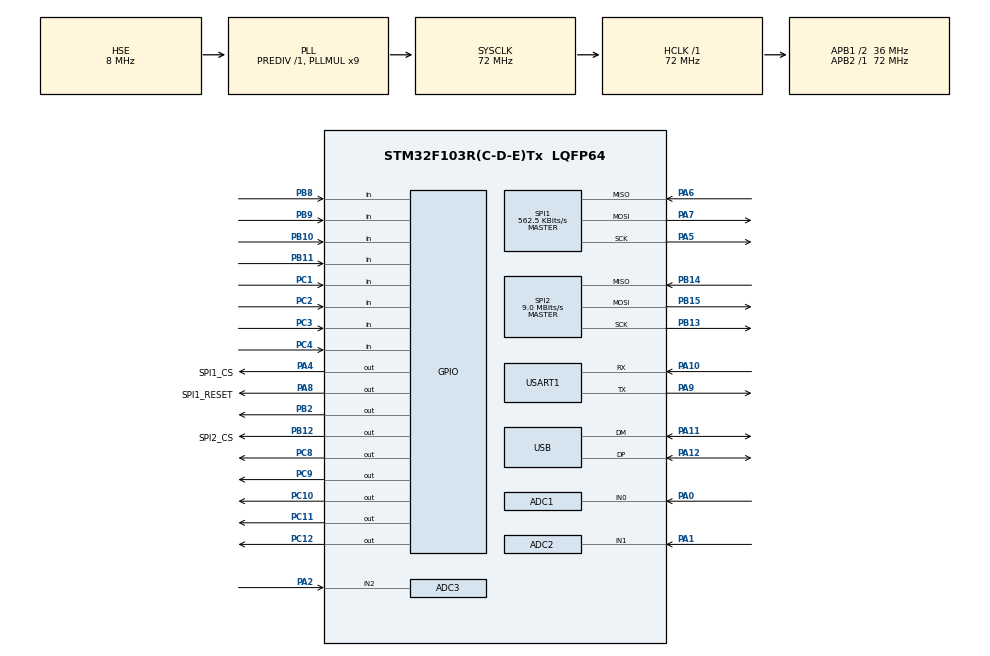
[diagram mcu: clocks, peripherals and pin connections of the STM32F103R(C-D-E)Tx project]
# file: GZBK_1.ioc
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ADC1.Channel-5\#ChannelRegularConversion=ADC_CHANNEL_0
ADC1.ContinuousConvMode=ENABLE
ADC1.NbrOfConversion=1
ADC1.NbrOfConversionFlag=1
ADC1.Rank-5\#ChannelRegularConversion=1
ADC1.SamplingTime-5\#ChannelRegularConversion=ADC_SAMPLETIME_239CYCLES_5
ADC1.master=1
ADC2.Channel-3\#ChannelRegularConversion=ADC_CHANNEL_1
ADC2.ContinuousConvMode=ENABLE
ADC2.NbrOfConversionFlag=1
ADC2.Rank-3\#ChannelRegularConversion=1
ADC2.SamplingTime-3\#ChannelRegularConversion=ADC_SAMPLETIME_1CYCLE_5
ADC3.Channel-0\#ChannelRegularConversion=ADC_CHANNEL_2
ADC3.ContinuousConvMode=ENABLE
ADC3.NbrOfConversion=1
ADC3.NbrOfConversionFlag=1
ADC3.Rank-0\#ChannelRegularConversion=1
ADC3.SamplingTime-0\#ChannelRegularConversion=ADC_SAMPLETIME_1CYCLE_5
Dma.ADC3.0.Direction=DMA_PERIPH_TO_MEMORY
Dma.ADC3.0.Instance=DMA2_Channel5
Dma.ADC3.0.MemDataAlignment=DMA_MDATAALIGN_HALFWORD
Dma.ADC3.0.MemInc=DMA_MINC_ENABLE
Dma.ADC3.0.Mode=DMA_CIRCULAR
Dma.ADC3.0.PeriphDataAlignment=DMA_PDATAALIGN_HALFWORD
Dma.ADC3.0.PeriphInc=DMA_PINC_DISABLE
Dma.ADC3.0.Priority=DMA_PRIORITY_VERY_HIGH
Dma.Request0=ADC3
Mcu.Family=STM32F1
Mcu.Name=STM32F103R(C-D-E)Tx
Mcu.Package=LQFP64
NVIC.DMA2_Channel4_5_IRQn=true\:0\:0\:false\:false\:true\:false\:true
NVIC.PriorityGroup=NVIC_PRIORITYGROUP_4
NVIC.USART1_IRQn=true\:0\:0\:false\:false\:true\:true\:true
NVIC.USB_LP_CAN1_RX0_IRQn=true\:0\:0\:false\:false\:true\:false\:true
PA0-WKUP.Signal=ADCx_IN0
PA1.Signal=ADCx_IN1
PA10.Mode=Asynchronous
PA10.Signal=USART1_RX
PA11.Mode=Device
PA11.Signal=USB_DM
PA12.Mode=Device
PA12.Signal=USB_DP
PA13.Mode=Serial_Wire
PA13.Signal=SYS_JTMS-SWDIO
PA14.Mode=Serial_Wire
PA14.Signal=SYS_JTCK-SWCLK
PA2.Signal=ADCx_IN2
PA4.GPIO_Label=SPI1_CS
PA4.GPIO_PuPd=GPIO_PULLDOWN
PA4.GPIO_Speed=GPIO_SPEED_FREQ_HIGH
PA4.PinState=GPIO_PIN_SET
PA4.Signal=GPIO_Output
PA5.Mode=Full_Duplex_Master
PA5.Signal=SPI1_SCK
PA6.Mode=Full_Duplex_Master
PA6.Signal=SPI1_MISO
PA7.Mode=Full_Duplex_Master
PA7.Signal=SPI1_MOSI
PA8.GPIO_Label=SPI1_RESET
PA8.Signal=GPIO_Output
PA9.Mode=Asynchronous
PA9.Signal=USART1_TX
PB10.GPIO_PuPd=GPIO_PULLDOWN
PB10.Signal=GPIO_Input
PB11.GPIO_PuPd=GPIO_PULLDOWN
PB11.Signal=GPIO_Input
PB12.GPIO_Label=SPI2_CS
PB12.GPIO_PuPd=GPIO_PULLUP
PB12.GPIO_Speed=GPIO_SPEED_FREQ_HIGH
PB12.PinState=GPIO_PIN_SET
PB12.Signal=GPIO_Output
PB13.GPIO_Mode=GPIO_MODE_AF_PP
PB13.Mode=Full_Duplex_Master
PB13.Signal=SPI2_SCK
PB14.GPIO_PuPd=GPIO_PULLUP
PB14.Mode=Full_Duplex_Master
PB14.Signal=SPI2_MISO
PB15.GPIO_Speed=GPIO_SPEED_FREQ_HIGH
PB15.Mode=Full_Duplex_Master
PB15.Signal=SPI2_MOSI
PB2.PinState=GPIO_PIN_SET
PB2.Signal=GPIO_Output
PB8.GPIO_PuPd=GPIO_PULLDOWN
PB8.Signal=GPIO_Input
PB9.GPIO_PuPd=GPIO_PULLDOWN
PB9.Signal=GPIO_Input
PC1.GPIO_PuPd=GPIO_PULLDOWN
PC1.Signal=GPIO_Input
PC10.GPIO_ModeDefaultOutputPP=GPIO_MODE_OUTPUT_PP
PC10.GPIO_PuPd=GPIO_NOPULL
PC10.GPIO_Speed=GPIO_SPEED_FREQ_HIGH
PC10.PinState=GPIO_PIN_SET
PC10.Signal=GPIO_Output
PC11.GPIO_Speed=GPIO_SPEED_FREQ_HIGH
PC11.Signal=GPIO_Output
PC12.GPIO_Speed=GPIO_SPEED_FREQ_HIGH
PC12.PinState=GPIO_PIN_SET
PC12.Signal=GPIO_Output
PC14-OSC32_IN.Mode=LSE-External-Oscillator
PC14-OSC32_IN.Signal=RCC_OSC32_IN
PC15-OSC32_OUT.Mode=LSE-External-Oscillator
PC15-OSC32_OUT.Signal=RCC_OSC32_OUT
PC2.GPIO_PuPd=GPIO_PULLDOWN
PC2.Signal=GPIO_Input
PC3.GPIO_PuPd=GPIO_PULLDOWN
PC3.Signal=GPIO_Input
PC4.GPIO_PuPd=GPIO_PULLDOWN
PC4.Signal=GPIO_Input
PC8.GPIO_ModeDefaultOutputPP=GPIO_MODE_OUTPUT_PP
PC8.GPIO_PuPd=GPIO_NOPULL
PC8.GPIO_Speed=GPIO_SPEED_FREQ_HIGH
PC8.PinState=GPIO_PIN_SET
PC8.Signal=GPIO_Output
PC9.GPIO_Speed=GPIO_SPEED_FREQ_HIGH
PC9.PinState=GPIO_PIN_SET
PC9.Signal=GPIO_Output
PD0-OSC_IN.Mode=HSE-External-Oscillator
PD0-OSC_IN.Signal=RCC_OSC_IN
PD1-OSC_OUT.Mode=HSE-External-Oscillator
PD1-OSC_OUT.Signal=RCC_OSC_OUT
ProjectManager.HeapSize=0x2000
ProjectManager.StackSize=0xA000
ProjectManager.TargetToolchain=MDK-ARM V5.27
RCC.ADCPresc=RCC_ADCPCLK2_DIV6
RCC.AHBFreq_Value=72000000
RCC.APB1CLKDivider=RCC_HCLK_DIV2
RCC.APB1Freq_Value=36000000
RCC.APB1TimFreq_Value=72000000
RCC.APB2Freq_Value=72000000
RCC.APB2TimFreq_Value=72000000
RCC.HCLKFreq_Value=72000000
RCC.PLLMUL=RCC_PLL_MUL9
RCC.PLLSourceVirtual=RCC_PLLSOURCE_HSE
RCC.SYSCLKFreq_VALUE=72000000
RCC.SYSCLKSource=RCC_SYSCLKSOURCE_PLLCLK
RCC.USBFreq_Value=48000000
RCC.USBPrescaler=RCC_USBCLKSOURCE_PLL_DIV1_5
SH.ADCx_IN0.0=ADC1_IN0,IN0
SH.ADCx_IN1.0=ADC2_IN1,IN1
SH.ADCx_IN2.0=ADC3_IN2,IN2
SPI1.BaudRatePrescaler=SPI_BAUDRATEPRESCALER_128
SPI1.CLKPhase=SPI_PHASE_2EDGE
SPI1.CLKPolarity=SPI_POLARITY_LOW
SPI1.CalculateBaudRate=562.5 KBits/s
SPI1.Direction=SPI_DIRECTION_2LINES
SPI1.FirstBit=SPI_FIRSTBIT_MSB
SPI1.Mode=SPI_MODE_MASTER
SPI1.VirtualType=VM_MASTER
SPI2.BaudRatePrescaler=SPI_BAUDRATEPRESCALER_4
SPI2.CLKPhase=SPI_PHASE_1EDGE
SPI2.CLKPolarity=SPI_POLARITY_HIGH
SPI2.CalculateBaudRate=9.0 MBits/s
SPI2.Direction=SPI_DIRECTION_2LINES
SPI2.Mode=SPI_MODE_MASTER
SPI2.VirtualType=VM_MASTER
USART1.VirtualMode=VM_ASYNC
USB_DEVICE.CLASS_NAME_FS=CDC
USB_DEVICE.VirtualMode=Cdc
USB_DEVICE.VirtualModeFS=Cdc_FS
VP_USB_DEVICE_VS_USB_DEVICE_CDC_FS.Mode=CDC_FS
board=custom

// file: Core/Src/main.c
/* USER CODE BEGIN Header */
/**
  ******************************************************************************
  * @file           : main.c
  * @brief          : Main program body
  ******************************************************************************
  * @attention
  *
  * <h2><center>&copy; Copyright (c) 2021 STMicroelectronics.
  * All rights reserved.</center></h2>
  *
  * This software component is licensed by ST under Ultimate Liberty license
  * SLA0044, the "License"; You may not use this file except in compliance with
  * the License. You may obtain a copy of the License at:
  *                             www.st.com/SLA0044
  *
  ******************************************************************************
  */
/* USER CODE END Header */
#include "main.h"
#include "adc.h"
#include "dma.h"
#include "spi.h"
#include "usart.h"
#include "usb_device.h"
#include "gpio.h"

/* USER CODE BEGIN Includes */
#include "drv_log.h"
#include "drv_cmd.h"
#include "drv_power_gpio.h"
#include "drv_power_dds.h"
/* USER CODE END Includes */

void SystemClock_Config(void);

int main(void)
{

  /* MCU Configuration--------------------------------------------------------*/

  /* Reset of all peripherals, Initializes the Flash interface and the Systick. */
  HAL_Init();

  /* Configure the system clock */
  SystemClock_Config();

  /* Initialize all configured peripherals */
  MX_GPIO_Init();
  MX_DMA_Init();
  MX_USART1_UART_Init();
  MX_USB_DEVICE_Init();
  MX_ADC1_Init();
  MX_ADC2_Init();
  MX_SPI1_Init();
  MX_SPI2_Init();
  MX_ADC3_Init();
  /* USER CODE BEGIN 2 */
  CommInit();//通信初始化
  AD9837_Init(0, 100000, 0, 0);
  LOG_PRINTF("Init Ok.");
  /* USER CODE END 2 */

  /* Infinite loop */
  /* USER CODE BEGIN WHILE */
while (1)
  {

     QueueOut();//主循环中将串口中断里放入队列中的数据通过通信协议解析，在通信协议回调函数中执行命令。
    /* USER CODE END WHILE */

  }
}

void SystemClock_Config(void)
{
  RCC_OscInitTypeDef RCC_OscInitStruct = {0};
  RCC_ClkInitTypeDef RCC_ClkInitStruct = {0};
  RCC_PeriphCLKInitTypeDef PeriphClkInit = {0};

  /** Initializes the RCC Oscillators according to the specified parameters
  * in the RCC_OscInitTypeDef structure.
  */
  RCC_OscInitStruct.OscillatorType = RCC_OSCILLATORTYPE_HSE;
  RCC_OscInitStruct.HSEState = RCC_HSE_ON;
  RCC_OscInitStruct.HSEPredivValue = RCC_HSE_PREDIV_DIV1;
  RCC_OscInitStruct.HSIState = RCC_HSI_ON;
  RCC_OscInitStruct.PLL.PLLState = RCC_PLL_ON;
  RCC_OscInitStruct.PLL.PLLSource = RCC_PLLSOURCE_HSE;
  RCC_OscInitStruct.PLL.PLLMUL = RCC_PLL_MUL9;
  if (HAL_RCC_OscConfig(&RCC_OscInitStruct) != HAL_OK)
  {
    Error_Handler();
  }
  /** Initializes the CPU, AHB and APB buses clocks
  */
  RCC_ClkInitStruct.ClockType = RCC_CLOCKTYPE_HCLK|RCC_CLOCKTYPE_SYSCLK
                              |RCC_CLOCKTYPE_PCLK1|RCC_CLOCKTYPE_PCLK2;
  RCC_ClkInitStruct.SYSCLKSource = RCC_SYSCLKSOURCE_PLLCLK;
  RCC_ClkInitStruct.AHBCLKDivider = RCC_SYSCLK_DIV1;
  RCC_ClkInitStruct.APB1CLKDivider = RCC_HCLK_DIV2;
  RCC_ClkInitStruct.APB2CLKDivider = RCC_HCLK_DIV1;

  if (HAL_RCC_ClockConfig(&RCC_ClkInitStruct, FLASH_LATENCY_2) != HAL_OK)
  {
    Error_Handler();
  }
  PeriphClkInit.PeriphClockSelection = RCC_PERIPHCLK_ADC|RCC_PERIPHCLK_USB;
  PeriphClkInit.AdcClockSelection = RCC_ADCPCLK2_DIV6;
  PeriphClkInit.UsbClockSelection = RCC_USBCLKSOURCE_PLL_DIV1_5;
  if (HAL_RCCEx_PeriphCLKConfig(&PeriphClkInit) != HAL_OK)
  {
    Error_Handler();
  }
}

void Error_Handler(void)
{
}

#ifdef  USE_FULL_ASSERT
/**
  * @brief  Reports the name of the source file and the source line number
  *         where the assert_param error has occurred.
  * @param  file: pointer to the source file name
  * @param  line: assert_param error line source number
  * @retval None
  */
void assert_failed(uint8_t *file, uint32_t line)
{
  /* USER CODE BEGIN 6 */
  /* User can add his own implementation to report the file name and line number,
     tex: printf("Wrong parameters value: file %s on line %d\r\n", file, line) */
    while (1) {
        LOG_ERROR("file %s on line %d\r\n", file, line);
    }
  /* USER CODE END 6 */
}
#endif /* USE_FULL_ASSERT */

/************************ (C) COPYRIGHT STMicroelectronics *****END OF FILE****/
